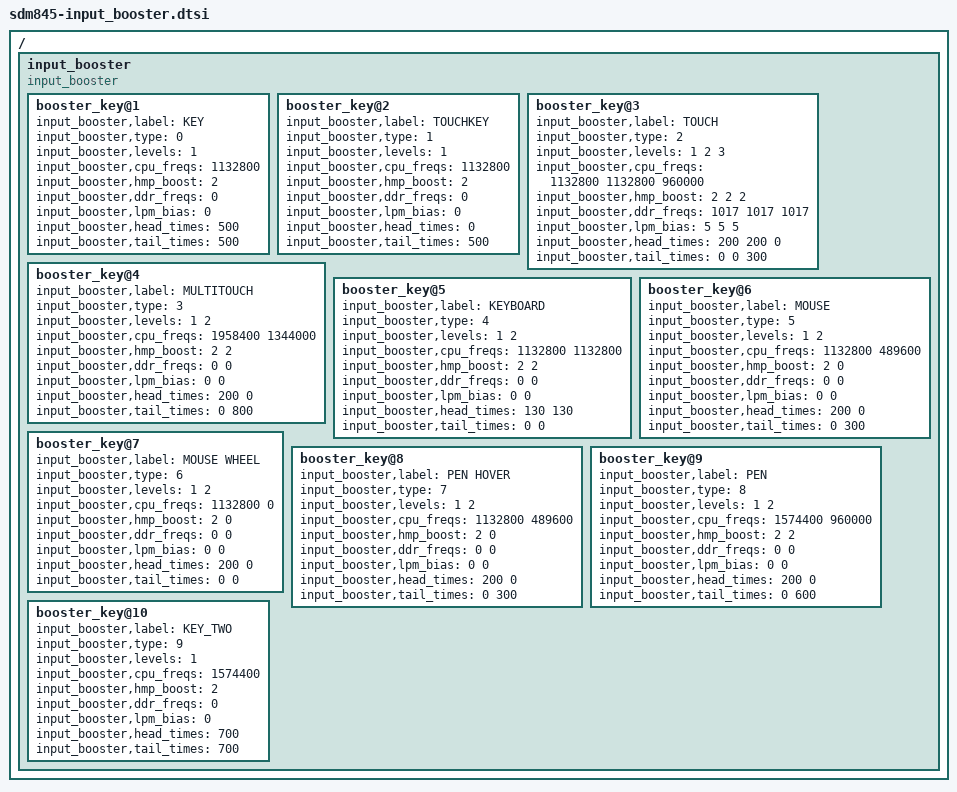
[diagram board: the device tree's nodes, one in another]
/* Copyright (c) 2012, The Linux Foundation. All rights reserved.
 *
 * This program is free software; you can redistribute it and/or modify
 * it under the terms of the GNU General Public License version 2 and
 * only version 2 as published by the Free Software Foundation.
 *
 * This program is distributed in the hope that it will be useful,
 * but WITHOUT ANY WARRANTY; without even the implied warranty of
 * MERCHANTABILITY or FITNESS FOR A PARTICULAR PURPOSE.  See the
 * GNU General Public License for more details.
 */

/{
	input_booster {
		status = "okay";
		compatible = "input_booster";
		#address-cells = <1>;
		#size-cells = <0>;

		booster_key@1 {
			input_booster,label = "KEY";
			input_booster,type = <0>;	/* BOOSTER_DEVICE_KEY */

			input_booster,levels = <1>;

			/* Frequency table */
			/* for level	:	1_Head */
			input_booster,cpu_freqs = <1132800>;
			input_booster,hmp_boost = <2>;
			input_booster,ddr_freqs = <0>;
			input_booster,lpm_bias = <0>;

			/* Time table */
			input_booster,head_times = <500>;
			input_booster,tail_times = <500>;
		};
		booster_key@2 {
			input_booster,label = "TOUCHKEY";
			input_booster,type = <1>;	/* BOOSTER_DEVICE_TOUCHKEY */

			input_booster,levels = <1>;

			/* Frequency table */
			/* for level	:	1_Head */
			input_booster,cpu_freqs = <1132800>;
			input_booster,hmp_boost = <2>;
			input_booster,ddr_freqs = <0>;
			input_booster,lpm_bias = <0>;

			/* Time table */
			input_booster,head_times = <0>;
			input_booster,tail_times = <500>;
		};
		booster_key@3 {
			input_booster,label = "TOUCH";
			input_booster,type = <2>;	/* BOOSTER_DEVICE_TOUCH */

			input_booster,levels = <1 2 3>;

			/* Frequency table */
			/* for level	:	1_Head, 2_Head, 2_Tail */
			input_booster,cpu_freqs = <1132800 1132800 960000>;
			input_booster,hmp_boost = <2 2 2>;
			input_booster,ddr_freqs = <1017 1017 1017>;
			input_booster,lpm_bias = <5 5 5>;

			/* Time table */
			input_booster,head_times = <200 200 0>;
			input_booster,tail_times = <0 0 300>;
		};
		booster_key@4 { // Input Booster +
			input_booster,label = "MULTITOUCH";
			input_booster,type = <3>;	/* BOOSTER_DEVICE_MULTITOUCH */

			input_booster,levels = <1 2>;

			/* Frequency table */
			/* for level	:	1_Head 2_Tail*/
			input_booster,cpu_freqs = <1958400 1344000>;
			input_booster,hmp_boost = <2 2>;
			input_booster,ddr_freqs = <0 0>;
			input_booster,lpm_bias = <0 0>;

			/* Time table */
			input_booster,head_times = <200 0>;
			input_booster,tail_times = <0 800>;
		};
		booster_key@5 {
			input_booster,label = "KEYBOARD";
			input_booster,type = <4>;	/* BOOSTER_DEVICE_KEYBOARD */

			input_booster,levels = <1 2>;

			/* Frequency table */
			/* for level	:	1_Head 2_Tail*/
			input_booster,cpu_freqs = <1132800 1132800>;
			input_booster,hmp_boost = <2 2>;
			input_booster,ddr_freqs = <0 0>;
			input_booster,lpm_bias = <0 0>;

			/* Time table */
			input_booster,head_times = <130 130>;
			input_booster,tail_times = <0 0>;
		};
		booster_key@6 {
			input_booster,label = "MOUSE";
			input_booster,type = <5>;	/* BOOSTER_DEVICE_MOUSE */

			input_booster,levels = <1 2>;

			/* Frequency table */
			/* for level	:	1_Head 2_Tail*/
			input_booster,cpu_freqs = <1132800 489600>;
			input_booster,hmp_boost = <2 0>;
			input_booster,ddr_freqs = <0 0>;
			input_booster,lpm_bias = <0 0>;

			/* Time table */
			input_booster,head_times = <200 0>;
			input_booster,tail_times = <0 300>;
		};
		booster_key@7 {
			input_booster,label = "MOUSE WHEEL";
			input_booster,type = <6>;	/* BOOSTER_DEVICE_MOUSE */

			input_booster,levels = <1 2>;

			/* Frequency table */
			/* for level	:	1_Head 2_Tail*/
			input_booster,cpu_freqs = <1132800 0>;
			input_booster,hmp_boost = <2 0>;
			input_booster,ddr_freqs = <0 0>;
			input_booster,lpm_bias = <0 0>;

			/* Time table */
			input_booster,head_times = <200 0>;
			input_booster,tail_times = <0 0>;
		};
		booster_key@8 {
			input_booster,label = "PEN HOVER";
			input_booster,type = <7>;	/* BOOSTER_DEVICE_MOUSE */

			input_booster,levels = <1 2>;

			/* Frequency table */
			/* for level	:	1_Head 2_Tail*/
			input_booster,cpu_freqs = <1132800 489600>;
			input_booster,hmp_boost = <2 0>;
			input_booster,ddr_freqs = <0 0>;
			input_booster,lpm_bias = <0 0>;

			/* Time table */
			input_booster,head_times = <200 0>;
			input_booster,tail_times = <0 300>;
		}; // Input Booster -
		booster_key@9 {
			input_booster,label = "PEN";
			input_booster,type = <8>;	/* BOOSTER_DEVICE_MOUSE */

			input_booster,levels = <1 2>;

			/* Frequency table */
			/* for level	:	1_Head 2_Tail*/
			input_booster,cpu_freqs = <1574400 960000>;
			input_booster,hmp_boost = <2 2>;
			input_booster,ddr_freqs = <0 0>;
			input_booster,lpm_bias = <0 0>;

			/* Time table */
			input_booster,head_times = <200 0>;
			input_booster,tail_times = <0 600>;
		}; // Input Booster -
		booster_key@10 {
			input_booster,label = "KEY_TWO";
			input_booster,type = <9>;	/* BOOSTER_DEVICE_KEY */

			input_booster,levels = <1>;

			/* Frequency table */
			/* for level	:	1_Head */
			input_booster,cpu_freqs = <1574400>;
			input_booster,hmp_boost = <2>;
			input_booster,ddr_freqs = <0>;
			input_booster,lpm_bias = <0>;

			/* Time table */
			input_booster,head_times = <700>;
			input_booster,tail_times = <700>;
		}; // Input Booster -
		/* If you need to add new key type, add it this position */
	};
};
